AUTOSAR XML (schema 4-0-3)
standard types defined: Boolean, UInt16
package /AUTOSAR_Platform/DataConstrs
  range DC_Boolean: raw 0..1
  range DC_UInt16: raw 0..65535
package /PATAC/MSM/ComponentTypes
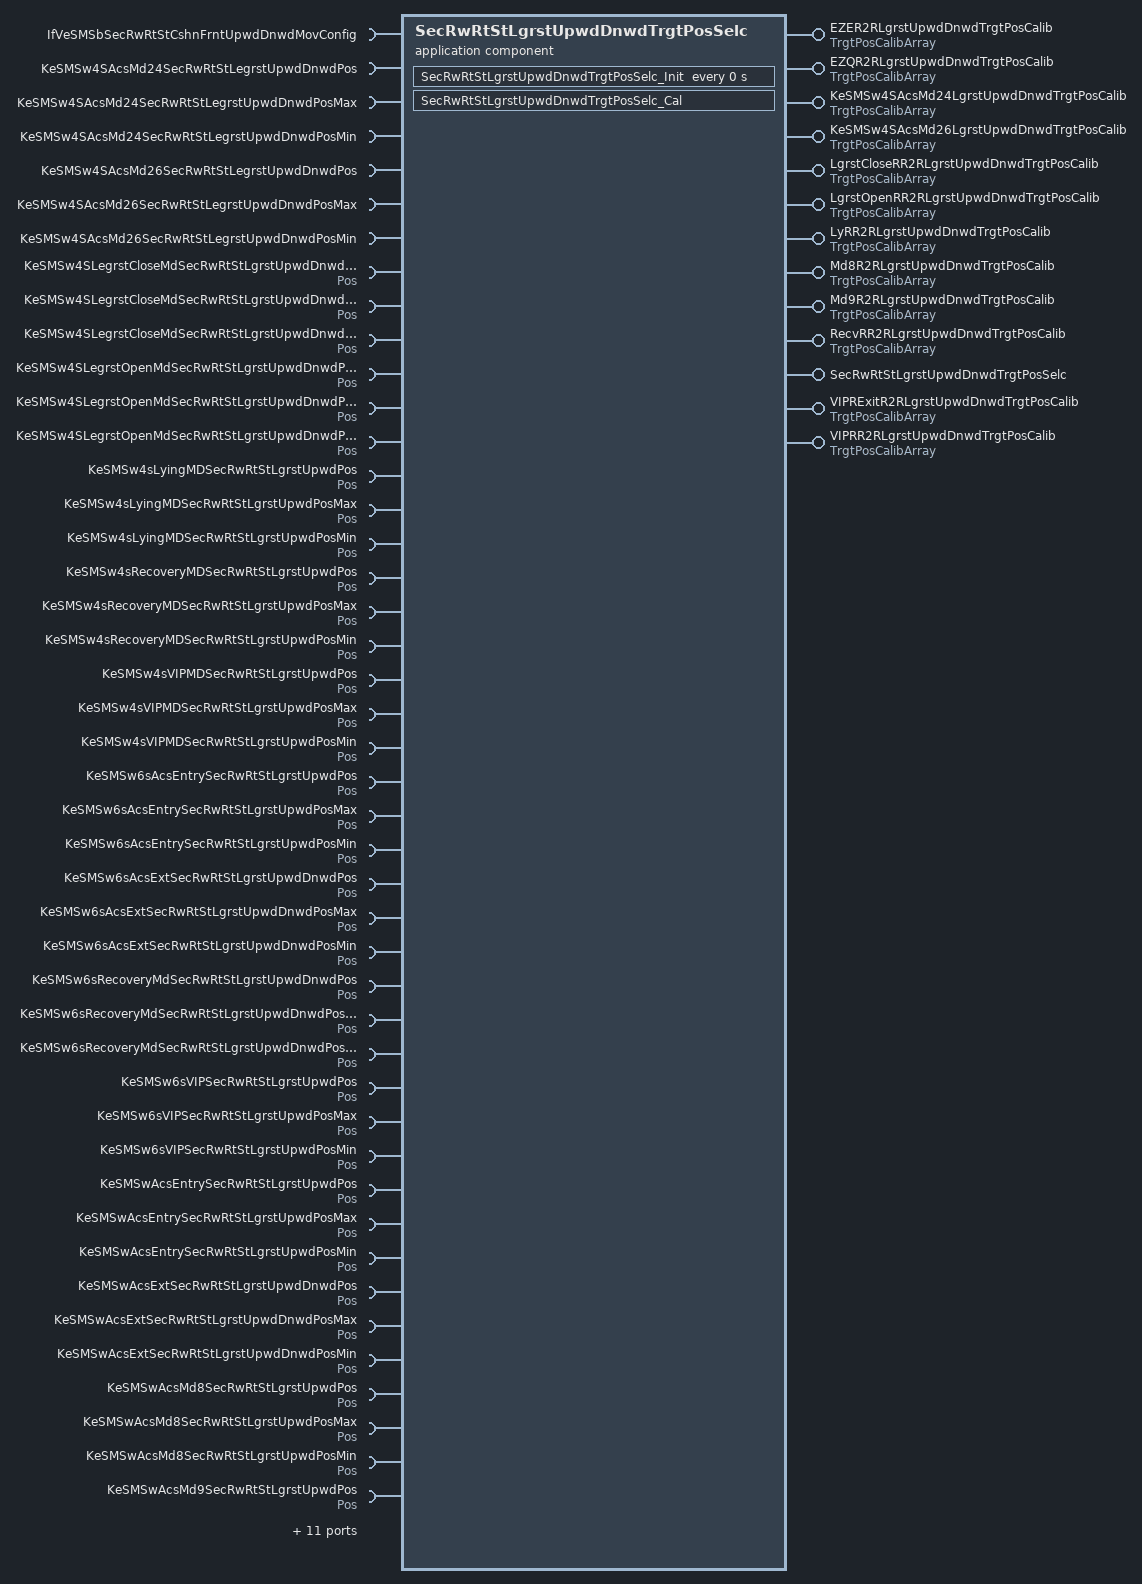
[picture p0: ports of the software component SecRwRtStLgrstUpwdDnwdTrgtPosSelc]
  application sw component type SecRwRtStLgrstUpwdDnwdTrgtPosSelc
    13 x provide port:
      EZER2RLgrstUpwdDnwdTrgtPosCalib: nonqueued-sender-com-spec{data-element=TrgtPosArray, init-value=[4095, 4095, 4095]}, provided-interface=TrgtPosCalibArray
      EZQR2RLgrstUpwdDnwdTrgtPosCalib: nonqueued-sender-com-spec{data-element=TrgtPosArray, init-value=[4095, 4095, 4095]}, provided-interface=TrgtPosCalibArray
      KeSMSw4SAcsMd24LgrstUpwdDnwdTrgtPosCalib: nonqueued-sender-com-spec{data-element=TrgtPosArray, init-value=[4095, 4095, 4095]}, provided-interface=TrgtPosCalibArray
      KeSMSw4SAcsMd26LgrstUpwdDnwdTrgtPosCalib: nonqueued-sender-com-spec{data-element=TrgtPosArray, init-value=[4095, 4095, 4095]}, provided-interface=TrgtPosCalibArray
      LgrstCloseRR2RLgrstUpwdDnwdTrgtPosCalib: nonqueued-sender-com-spec{data-element=TrgtPosArray, init-value=[4095, 4095, 4095]}, provided-interface=TrgtPosCalibArray
      LgrstOpenRR2RLgrstUpwdDnwdTrgtPosCalib: nonqueued-sender-com-spec{data-element=TrgtPosArray, init-value=[4095, 4095, 4095]}, provided-interface=TrgtPosCalibArray
      LyRR2RLgrstUpwdDnwdTrgtPosCalib: nonqueued-sender-com-spec{data-element=TrgtPosArray, init-value=[4095, 4095, 4095]}, provided-interface=TrgtPosCalibArray
      Md8R2RLgrstUpwdDnwdTrgtPosCalib: nonqueued-sender-com-spec{data-element=TrgtPosArray, init-value=[4095, 4095, 4095]}, provided-interface=TrgtPosCalibArray
      Md9R2RLgrstUpwdDnwdTrgtPosCalib: nonqueued-sender-com-spec{data-element=TrgtPosArray, init-value=[4095, 4095, 4095]}, provided-interface=TrgtPosCalibArray
      RecvRR2RLgrstUpwdDnwdTrgtPosCalib: nonqueued-sender-com-spec{data-element=TrgtPosArray, init-value=[4095, 4095, 4095]}, provided-interface=TrgtPosCalibArray
      SecRwRtStLgrstUpwdDnwdTrgtPosSelc: server-com-spec{operation=Cal, queue-length=1}, provided-interface=SecRwRtStLgrstUpwdDnwdTrgtPosSelc
      VIPRExitR2RLgrstUpwdDnwdTrgtPosCalib: nonqueued-sender-com-spec{data-element=TrgtPosArray, init-value=[4095, 4095, 4095]}, provided-interface=TrgtPosCalibArray
      VIPRR2RLgrstUpwdDnwdTrgtPosCalib: nonqueued-sender-com-spec{data-element=TrgtPosArray, init-value=[4095, 4095, 4095]}, provided-interface=TrgtPosCalibArray
    55 x require port:
      IfVeSMSbSecRwRtStCshnFrntUpwdDnwdMovConfig: nonqueued-receiver-com-spec{data-element=Val, filter=data-filter-type=ALWAYS, init-value=0}, required-interface=IfVeSMSbSecRwRtStCshnFrntUpwdDnwdMovConfig
      KeSMSw4SAcsMd24SecRwRtStLegrstUpwdDnwdPos: parameter-require-com-spec{init-value=0, parameter=KeSMSw4SAcsMd24SecRwRtStLegrstUpwdDnwdPos/Val}, required-interface=KeSMSw4SAcsMd24SecRwRtStLegrstUpwdDnwdPos
      KeSMSw4SAcsMd24SecRwRtStLegrstUpwdDnwdPosMax: parameter-require-com-spec{init-value=0, parameter=KeSMSw4SAcsMd24SecRwRtStLegrstUpwdDnwdPosMax/Val}, required-interface=KeSMSw4SAcsMd24SecRwRtStLegrstUpwdDnwdPosMax
      KeSMSw4SAcsMd24SecRwRtStLegrstUpwdDnwdPosMin: parameter-require-com-spec{init-value=0, parameter=KeSMSw4SAcsMd24SecRwRtStLegrstUpwdDnwdPosMin/Val}, required-interface=KeSMSw4SAcsMd24SecRwRtStLegrstUpwdDnwdPosMin
      KeSMSw4SAcsMd26SecRwRtStLegrstUpwdDnwdPos: parameter-require-com-spec{init-value=0, parameter=KeSMSw4SAcsMd26SecRwRtStLegrstUpwdDnwdPos/Val}, required-interface=KeSMSw4SAcsMd26SecRwRtStLegrstUpwdDnwdPos
      KeSMSw4SAcsMd26SecRwRtStLegrstUpwdDnwdPosMax: parameter-require-com-spec{init-value=0, parameter=KeSMSw4SAcsMd26SecRwRtStLegrstUpwdDnwdPosMax/Val}, required-interface=KeSMSw4SAcsMd26SecRwRtStLegrstUpwdDnwdPosMax
      KeSMSw4SAcsMd26SecRwRtStLegrstUpwdDnwdPosMin: parameter-require-com-spec{init-value=0, parameter=KeSMSw4SAcsMd26SecRwRtStLegrstUpwdDnwdPosMin/Val}, required-interface=KeSMSw4SAcsMd26SecRwRtStLegrstUpwdDnwdPosMin
      KeSMSw4SLegrstCloseMdSecRwRtStLgrstUpwdDnwdPos: parameter-require-com-spec{init-value=0, parameter=Pos/Val}, required-interface=Pos
      KeSMSw4SLegrstCloseMdSecRwRtStLgrstUpwdDnwdPosMax: parameter-require-com-spec{init-value=0, parameter=Pos/Val}, required-interface=Pos
      KeSMSw4SLegrstCloseMdSecRwRtStLgrstUpwdDnwdPosMin: parameter-require-com-spec{init-value=0, parameter=Pos/Val}, required-interface=Pos
      KeSMSw4SLegrstOpenMdSecRwRtStLgrstUpwdDnwdPos: parameter-require-com-spec{init-value=0, parameter=Pos/Val}, required-interface=Pos
      KeSMSw4SLegrstOpenMdSecRwRtStLgrstUpwdDnwdPosMax: parameter-require-com-spec{init-value=0, parameter=Pos/Val}, required-interface=Pos
      KeSMSw4SLegrstOpenMdSecRwRtStLgrstUpwdDnwdPosMin: parameter-require-com-spec{init-value=0, parameter=Pos/Val}, required-interface=Pos
      KeSMSw4sLyingMDSecRwRtStLgrstUpwdPos: parameter-require-com-spec{init-value=0, parameter=Pos/Val}, required-interface=Pos
      KeSMSw4sLyingMDSecRwRtStLgrstUpwdPosMax: parameter-require-com-spec{init-value=0, parameter=Pos/Val}, required-interface=Pos
      KeSMSw4sLyingMDSecRwRtStLgrstUpwdPosMin: parameter-require-com-spec{init-value=0, parameter=Pos/Val}, required-interface=Pos
      KeSMSw4sRecoveryMDSecRwRtStLgrstUpwdPos: parameter-require-com-spec{init-value=0, parameter=Pos/Val}, required-interface=Pos
      KeSMSw4sRecoveryMDSecRwRtStLgrstUpwdPosMax: parameter-require-com-spec{init-value=0, parameter=Pos/Val}, required-interface=Pos
      KeSMSw4sRecoveryMDSecRwRtStLgrstUpwdPosMin: parameter-require-com-spec{init-value=0, parameter=Pos/Val}, required-interface=Pos
      KeSMSw4sVIPMDSecRwRtStLgrstUpwdPos: parameter-require-com-spec{init-value=0, parameter=Pos/Val}, required-interface=Pos
      KeSMSw4sVIPMDSecRwRtStLgrstUpwdPosMax: parameter-require-com-spec{init-value=0, parameter=Pos/Val}, required-interface=Pos
      KeSMSw4sVIPMDSecRwRtStLgrstUpwdPosMin: parameter-require-com-spec{init-value=0, parameter=Pos/Val}, required-interface=Pos
      KeSMSw6sAcsEntrySecRwRtStLgrstUpwdPos: parameter-require-com-spec{init-value=0, parameter=Pos/Val}, required-interface=Pos
      KeSMSw6sAcsEntrySecRwRtStLgrstUpwdPosMax: parameter-require-com-spec{init-value=0, parameter=Pos/Val}, required-interface=Pos
      KeSMSw6sAcsEntrySecRwRtStLgrstUpwdPosMin: parameter-require-com-spec{init-value=0, parameter=Pos/Val}, required-interface=Pos
      KeSMSw6sAcsExtSecRwRtStLgrstUpwdDnwdPos: parameter-require-com-spec{init-value=0, parameter=Pos/Val}, required-interface=Pos
      KeSMSw6sAcsExtSecRwRtStLgrstUpwdDnwdPosMax: parameter-require-com-spec{init-value=0, parameter=Pos/Val}, required-interface=Pos
      KeSMSw6sAcsExtSecRwRtStLgrstUpwdDnwdPosMin: parameter-require-com-spec{init-value=0, parameter=Pos/Val}, required-interface=Pos
      KeSMSw6sRecoveryMdSecRwRtStLgrstUpwdDnwdPos: parameter-require-com-spec{init-value=0, parameter=Pos/Val}, required-interface=Pos
      KeSMSw6sRecoveryMdSecRwRtStLgrstUpwdDnwdPosMax: parameter-require-com-spec{init-value=0, parameter=Pos/Val}, required-interface=Pos
      KeSMSw6sRecoveryMdSecRwRtStLgrstUpwdDnwdPosMin: parameter-require-com-spec{init-value=0, parameter=Pos/Val}, required-interface=Pos
      KeSMSw6sVIPSecRwRtStLgrstUpwdPos: parameter-require-com-spec{init-value=4000, parameter=Pos/Val}, required-interface=Pos
      KeSMSw6sVIPSecRwRtStLgrstUpwdPosMax: parameter-require-com-spec{init-value=4000, parameter=Pos/Val}, required-interface=Pos
      KeSMSw6sVIPSecRwRtStLgrstUpwdPosMin: parameter-require-com-spec{init-value=20, parameter=Pos/Val}, required-interface=Pos
      KeSMSwAcsEntrySecRwRtStLgrstUpwdPos: parameter-require-com-spec{init-value=0, parameter=Pos/Val}, required-interface=Pos
      KeSMSwAcsEntrySecRwRtStLgrstUpwdPosMax: parameter-require-com-spec{init-value=0, parameter=Pos/Val}, required-interface=Pos
      KeSMSwAcsEntrySecRwRtStLgrstUpwdPosMin: parameter-require-com-spec{init-value=0, parameter=Pos/Val}, required-interface=Pos
      KeSMSwAcsExtSecRwRtStLgrstUpwdDnwdPos: parameter-require-com-spec{init-value=0, parameter=Pos/Val}, required-interface=Pos
      KeSMSwAcsExtSecRwRtStLgrstUpwdDnwdPosMax: parameter-require-com-spec{init-value=0, parameter=Pos/Val}, required-interface=Pos
      KeSMSwAcsExtSecRwRtStLgrstUpwdDnwdPosMin: parameter-require-com-spec{init-value=0, parameter=Pos/Val}, required-interface=Pos
      KeSMSwAcsMd8SecRwRtStLgrstUpwdPos: parameter-require-com-spec{init-value=0, parameter=Pos/Val}, required-interface=Pos
      KeSMSwAcsMd8SecRwRtStLgrstUpwdPosMax: parameter-require-com-spec{init-value=0, parameter=Pos/Val}, required-interface=Pos
      KeSMSwAcsMd8SecRwRtStLgrstUpwdPosMin: parameter-require-com-spec{init-value=0, parameter=Pos/Val}, required-interface=Pos
      KeSMSwAcsMd9SecRwRtStLgrstUpwdPos: parameter-require-com-spec{init-value=0, parameter=Pos/Val}, required-interface=Pos
      KeSMSwAcsMd9SecRwRtStLgrstUpwdPosMax: parameter-require-com-spec{init-value=0, parameter=Pos/Val}, required-interface=Pos
      KeSMSwAcsMd9SecRwRtStLgrstUpwdPosMin: parameter-require-com-spec{init-value=0, parameter=Pos/Val}, required-interface=Pos
      KeSMSwRecoveryMdSecRwRtStLgrstUpwdDnwdPos: parameter-require-com-spec{init-value=0, parameter=Pos/Val}, required-interface=Pos
      KeSMSwRecoveryMdSecRwRtStLgrstUpwdDnwdPosMax: parameter-require-com-spec{init-value=0, parameter=Pos/Val}, required-interface=Pos
      KeSMSwRecoveryMdSecRwRtStLgrstUpwdDnwdPosMin: parameter-require-com-spec{init-value=0, parameter=Pos/Val}, required-interface=Pos
      KeSMSwVIPSecRwRtStLgrstUpwdPos: parameter-require-com-spec{init-value=4000, parameter=Pos/Val}, required-interface=Pos
      KeSMSwVIPSecRwRtStLgrstUpwdPosMax: parameter-require-com-spec{init-value=4000, parameter=Pos/Val}, required-interface=Pos
      KeSMSwVIPSecRwRtStLgrstUpwdPosMin: parameter-require-com-spec{init-value=20, parameter=Pos/Val}, required-interface=Pos
      StNumFlg: required-interface=StNumFlg
        required-com-specs:
          data-element=Is4s, filter=data-filter-type=ALWAYS, init-value=0
          data-element=Is6s, filter=data-filter-type=ALWAYS, init-value=0
          data-element=Is6s7s, filter=data-filter-type=ALWAYS, init-value=0
          data-element=Is7s, filter=data-filter-type=ALWAYS, init-value=0
      VIPR557TrgtPos: required-com-specs=[VIPR557TrgtPos/Get, VIPR557TrgtPos/Set], required-interface=VIPR557TrgtPos
      VIPRExit557TrgtPos: required-com-specs=[VIPRExit557TrgtPos/Get, VIPRExit557TrgtPos/Set], required-interface=VIPRExit557TrgtPos
    behavior SecRwRtStLgrstUpwdDnwdTrgtPosSelc_InternalBehavior
      operation invoked event OIT_SecRwRtStLgrstUpwdDnwdTrgtPosSelc_Cal_SecRwRtStLgrstUpwdDnwdTrgtPosSelc_Cal: start-on-event=SecRwRtStLgrstUpwdDnwdTrgtPosSelc_Cal, operation=SecRwRtStLgrstUpwdDnwdTrgtPosSelc.Cal
      timing event SecRwRtStLgrstUpwdDnwdTrgtPosSelc_InitEvent: start-on-event=SecRwRtStLgrstUpwdDnwdTrgtPosSelc_Init, period=0
      runnable SecRwRtStLgrstUpwdDnwdTrgtPosSelc_Cal
        data-receive-point-by-arguments:
          5 x access:
            REC_IfVeSMSbSecRwRtStCshnFrntUpwdDnwdMovConfig_Val: accessed-variable=IfVeSMSbSecRwRtStCshnFrntUpwdDnwdMovConfig.Val
            REC_StNumFlg_Is4s: accessed-variable=StNumFlg.Is4s
            REC_StNumFlg_Is6s: accessed-variable=StNumFlg.Is6s
            REC_StNumFlg_Is6s7s: accessed-variable=StNumFlg.Is6s7s
            REC_StNumFlg_Is7s: accessed-variable=StNumFlg.Is7s
        data-send-points:
          12 x access:
            SEND_EZER2RLgrstUpwdDnwdTrgtPosCalib_TrgtPosArray: accessed-variable=EZER2RLgrstUpwdDnwdTrgtPosCalib.TrgtPosArray
            SEND_EZQR2RLgrstUpwdDnwdTrgtPosCalib_TrgtPosArray: accessed-variable=EZQR2RLgrstUpwdDnwdTrgtPosCalib.TrgtPosArray
            SEND_KeSMSw4SAcsMd24LgrstUpwdDnwdTrgtPosCalib_TrgtPosArray: accessed-variable=KeSMSw4SAcsMd24LgrstUpwdDnwdTrgtPosCalib.TrgtPosArray
            SEND_KeSMSw4SAcsMd26LgrstUpwdDnwdTrgtPosCalib_TrgtPosArray: accessed-variable=KeSMSw4SAcsMd26LgrstUpwdDnwdTrgtPosCalib.TrgtPosArray
            SEND_LgrstCloseRR2RLgrstUpwdDnwdTrgtPosCalib_TrgtPosArray: accessed-variable=LgrstCloseRR2RLgrstUpwdDnwdTrgtPosCalib.TrgtPosArray
            SEND_LgrstOpenRR2RLgrstUpwdDnwdTrgtPosCalib_TrgtPosArray: accessed-variable=LgrstOpenRR2RLgrstUpwdDnwdTrgtPosCalib.TrgtPosArray
            SEND_LyRR2RLgrstUpwdDnwdTrgtPosCalib_TrgtPosArray: accessed-variable=LyRR2RLgrstUpwdDnwdTrgtPosCalib.TrgtPosArray
            SEND_Md8R2RLgrstUpwdDnwdTrgtPosCalib_TrgtPosArray: accessed-variable=Md8R2RLgrstUpwdDnwdTrgtPosCalib.TrgtPosArray
            SEND_Md9R2RLgrstUpwdDnwdTrgtPosCalib_TrgtPosArray: accessed-variable=Md9R2RLgrstUpwdDnwdTrgtPosCalib.TrgtPosArray
            SEND_RecvRR2RLgrstUpwdDnwdTrgtPosCalib_TrgtPosArray: accessed-variable=RecvRR2RLgrstUpwdDnwdTrgtPosCalib.TrgtPosArray
            SEND_VIPRExitR2RLgrstUpwdDnwdTrgtPosCalib_TrgtPosArray: accessed-variable=VIPRExitR2RLgrstUpwdDnwdTrgtPosCalib.TrgtPosArray
            SEND_VIPRR2RLgrstUpwdDnwdTrgtPosCalib_TrgtPosArray: accessed-variable=VIPRR2RLgrstUpwdDnwdTrgtPosCalib.TrgtPosArray
        51 x parameter access:
          PA_KeSMSw4SAcsMd24SecRwRtStLegrstUpwdDnwdPos_Val: accessed-parameter=KeSMSw4SAcsMd24SecRwRtStLegrstUpwdDnwdPos.Val
          PA_KeSMSw4SAcsMd24SecRwRtStLegrstUpwdDnwdPosMax_Val: accessed-parameter=KeSMSw4SAcsMd24SecRwRtStLegrstUpwdDnwdPosMax.Val
          PA_KeSMSw4SAcsMd24SecRwRtStLegrstUpwdDnwdPosMin_Val: accessed-parameter=KeSMSw4SAcsMd24SecRwRtStLegrstUpwdDnwdPosMin.Val
          PA_KeSMSw4SAcsMd26SecRwRtStLegrstUpwdDnwdPos_Val: accessed-parameter=KeSMSw4SAcsMd26SecRwRtStLegrstUpwdDnwdPos.Val
          PA_KeSMSw4SAcsMd26SecRwRtStLegrstUpwdDnwdPosMax_Val: accessed-parameter=KeSMSw4SAcsMd26SecRwRtStLegrstUpwdDnwdPosMax.Val
          PA_KeSMSw4SAcsMd26SecRwRtStLegrstUpwdDnwdPosMin_Val: accessed-parameter=KeSMSw4SAcsMd26SecRwRtStLegrstUpwdDnwdPosMin.Val
          PA_KeSMSw4SLegrstCloseMdSecRwRtStLgrstUpwdDnwdPos_Val: accessed-parameter=KeSMSw4SLegrstCloseMdSecRwRtStLgrstUpwdDnwdPos.Val
          PA_KeSMSw4SLegrstCloseMdSecRwRtStLgrstUpwdDnwdPosMax_Val: accessed-parameter=KeSMSw4SLegrstCloseMdSecRwRtStLgrstUpwdDnwdPosMax.Val
          PA_KeSMSw4SLegrstCloseMdSecRwRtStLgrstUpwdDnwdPosMin_Val: accessed-parameter=KeSMSw4SLegrstCloseMdSecRwRtStLgrstUpwdDnwdPosMin.Val
          PA_KeSMSw4SLegrstOpenMdSecRwRtStLgrstUpwdDnwdPos_Val: accessed-parameter=KeSMSw4SLegrstOpenMdSecRwRtStLgrstUpwdDnwdPos.Val
          PA_KeSMSw4SLegrstOpenMdSecRwRtStLgrstUpwdDnwdPosMax_Val: accessed-parameter=KeSMSw4SLegrstOpenMdSecRwRtStLgrstUpwdDnwdPosMax.Val
          PA_KeSMSw4SLegrstOpenMdSecRwRtStLgrstUpwdDnwdPosMin_Val: accessed-parameter=KeSMSw4SLegrstOpenMdSecRwRtStLgrstUpwdDnwdPosMin.Val
          PA_KeSMSw4sLyingMDSecRwRtStLgrstUpwdPos_Val: accessed-parameter=KeSMSw4sLyingMDSecRwRtStLgrstUpwdPos.Val
          PA_KeSMSw4sLyingMDSecRwRtStLgrstUpwdPosMax_Val: accessed-parameter=KeSMSw4sLyingMDSecRwRtStLgrstUpwdPosMax.Val
          PA_KeSMSw4sLyingMDSecRwRtStLgrstUpwdPosMin_Val: accessed-parameter=KeSMSw4sLyingMDSecRwRtStLgrstUpwdPosMin.Val
          PA_KeSMSw4sRecoveryMDSecRwRtStLgrstUpwdPos_Val: accessed-parameter=KeSMSw4sRecoveryMDSecRwRtStLgrstUpwdPos.Val
          PA_KeSMSw4sRecoveryMDSecRwRtStLgrstUpwdPosMax_Val: accessed-parameter=KeSMSw4sRecoveryMDSecRwRtStLgrstUpwdPosMax.Val
          PA_KeSMSw4sRecoveryMDSecRwRtStLgrstUpwdPosMin_Val: accessed-parameter=KeSMSw4sRecoveryMDSecRwRtStLgrstUpwdPosMin.Val
          PA_KeSMSw4sVIPMDSecRwRtStLgrstUpwdPos_Val: accessed-parameter=KeSMSw4sVIPMDSecRwRtStLgrstUpwdPos.Val
          PA_KeSMSw4sVIPMDSecRwRtStLgrstUpwdPosMax_Val: accessed-parameter=KeSMSw4sVIPMDSecRwRtStLgrstUpwdPosMax.Val
          PA_KeSMSw4sVIPMDSecRwRtStLgrstUpwdPosMin_Val: accessed-parameter=KeSMSw4sVIPMDSecRwRtStLgrstUpwdPosMin.Val
          PA_KeSMSw6sAcsEntrySecRwRtStLgrstUpwdPos_Val: accessed-parameter=KeSMSw6sAcsEntrySecRwRtStLgrstUpwdPos.Val
          PA_KeSMSw6sAcsEntrySecRwRtStLgrstUpwdPosMax_Val: accessed-parameter=KeSMSw6sAcsEntrySecRwRtStLgrstUpwdPosMax.Val
          PA_KeSMSw6sAcsEntrySecRwRtStLgrstUpwdPosMin_Val: accessed-parameter=KeSMSw6sAcsEntrySecRwRtStLgrstUpwdPosMin.Val
          PA_KeSMSw6sAcsExtSecRwRtStLgrstUpwdDnwdPos_Val: accessed-parameter=KeSMSw6sAcsExtSecRwRtStLgrstUpwdDnwdPos.Val
          PA_KeSMSw6sAcsExtSecRwRtStLgrstUpwdDnwdPosMax_Val: accessed-parameter=KeSMSw6sAcsExtSecRwRtStLgrstUpwdDnwdPosMax.Val
          PA_KeSMSw6sAcsExtSecRwRtStLgrstUpwdDnwdPosMin_Val: accessed-parameter=KeSMSw6sAcsExtSecRwRtStLgrstUpwdDnwdPosMin.Val
          PA_KeSMSw6sRecoveryMdSecRwRtStLgrstUpwdDnwdPos_Val: accessed-parameter=KeSMSw6sRecoveryMdSecRwRtStLgrstUpwdDnwdPos.Val
          PA_KeSMSw6sRecoveryMdSecRwRtStLgrstUpwdDnwdPosMax_Val: accessed-parameter=KeSMSw6sRecoveryMdSecRwRtStLgrstUpwdDnwdPosMax.Val
          PA_KeSMSw6sRecoveryMdSecRwRtStLgrstUpwdDnwdPosMin_Val: accessed-parameter=KeSMSw6sRecoveryMdSecRwRtStLgrstUpwdDnwdPosMin.Val
          PA_KeSMSw6sVIPSecRwRtStLgrstUpwdPos_Val: accessed-parameter=KeSMSw6sVIPSecRwRtStLgrstUpwdPos.Val
          PA_KeSMSw6sVIPSecRwRtStLgrstUpwdPosMax_Val: accessed-parameter=KeSMSw6sVIPSecRwRtStLgrstUpwdPosMax.Val
          PA_KeSMSw6sVIPSecRwRtStLgrstUpwdPosMin_Val: accessed-parameter=KeSMSw6sVIPSecRwRtStLgrstUpwdPosMin.Val
          PA_KeSMSwAcsEntrySecRwRtStLgrstUpwdPos_Val: accessed-parameter=KeSMSwAcsEntrySecRwRtStLgrstUpwdPos.Val
          PA_KeSMSwAcsEntrySecRwRtStLgrstUpwdPosMax_Val: accessed-parameter=KeSMSwAcsEntrySecRwRtStLgrstUpwdPosMax.Val
          PA_KeSMSwAcsEntrySecRwRtStLgrstUpwdPosMin_Val: accessed-parameter=KeSMSwAcsEntrySecRwRtStLgrstUpwdPosMin.Val
          PA_KeSMSwAcsExtSecRwRtStLgrstUpwdDnwdPos_Val: accessed-parameter=KeSMSwAcsExtSecRwRtStLgrstUpwdDnwdPos.Val
          PA_KeSMSwAcsExtSecRwRtStLgrstUpwdDnwdPosMax_Val: accessed-parameter=KeSMSwAcsExtSecRwRtStLgrstUpwdDnwdPosMax.Val
          PA_KeSMSwAcsExtSecRwRtStLgrstUpwdDnwdPosMin_Val: accessed-parameter=KeSMSwAcsExtSecRwRtStLgrstUpwdDnwdPosMin.Val
          PA_KeSMSwAcsMd8SecRwRtStLgrstUpwdPos_Val: accessed-parameter=KeSMSwAcsMd8SecRwRtStLgrstUpwdPos.Val
          PA_KeSMSwAcsMd8SecRwRtStLgrstUpwdPosMax_Val: accessed-parameter=KeSMSwAcsMd8SecRwRtStLgrstUpwdPosMax.Val
          PA_KeSMSwAcsMd8SecRwRtStLgrstUpwdPosMin_Val: accessed-parameter=KeSMSwAcsMd8SecRwRtStLgrstUpwdPosMin.Val
          PA_KeSMSwAcsMd9SecRwRtStLgrstUpwdPos_Val: accessed-parameter=KeSMSwAcsMd9SecRwRtStLgrstUpwdPos.Val
          PA_KeSMSwAcsMd9SecRwRtStLgrstUpwdPosMax_Val: accessed-parameter=KeSMSwAcsMd9SecRwRtStLgrstUpwdPosMax.Val
          PA_KeSMSwAcsMd9SecRwRtStLgrstUpwdPosMin_Val: accessed-parameter=KeSMSwAcsMd9SecRwRtStLgrstUpwdPosMin.Val
          PA_KeSMSwRecoveryMdSecRwRtStLgrstUpwdDnwdPos_Val: accessed-parameter=KeSMSwRecoveryMdSecRwRtStLgrstUpwdDnwdPos.Val
          PA_KeSMSwRecoveryMdSecRwRtStLgrstUpwdDnwdPosMax_Val: accessed-parameter=KeSMSwRecoveryMdSecRwRtStLgrstUpwdDnwdPosMax.Val
          PA_KeSMSwRecoveryMdSecRwRtStLgrstUpwdDnwdPosMin_Val: accessed-parameter=KeSMSwRecoveryMdSecRwRtStLgrstUpwdDnwdPosMin.Val
          PA_KeSMSwVIPSecRwRtStLgrstUpwdPos_Val: accessed-parameter=KeSMSwVIPSecRwRtStLgrstUpwdPos.Val
          PA_KeSMSwVIPSecRwRtStLgrstUpwdPosMax_Val: accessed-parameter=KeSMSwVIPSecRwRtStLgrstUpwdPosMax.Val
          PA_KeSMSwVIPSecRwRtStLgrstUpwdPosMin_Val: accessed-parameter=KeSMSwVIPSecRwRtStLgrstUpwdPosMin.Val
        sync call SC_VIPR557TrgtPos_Get: operation=VIPR557TrgtPos.Get, timeout=0
        sync call SC_VIPRExit557TrgtPos_Get: operation=VIPRExit557TrgtPos.Get, timeout=0
      runnable SecRwRtStLgrstUpwdDnwdTrgtPosSelc_Init
        51 x parameter access:
          PA_KeSMSw4SAcsMd24SecRwRtStLegrstUpwdDnwdPos_Val: accessed-parameter=KeSMSw4SAcsMd24SecRwRtStLegrstUpwdDnwdPos.Val
          PA_KeSMSw4SAcsMd24SecRwRtStLegrstUpwdDnwdPosMax_Val: accessed-parameter=KeSMSw4SAcsMd24SecRwRtStLegrstUpwdDnwdPosMax.Val
          PA_KeSMSw4SAcsMd24SecRwRtStLegrstUpwdDnwdPosMin_Val: accessed-parameter=KeSMSw4SAcsMd24SecRwRtStLegrstUpwdDnwdPosMin.Val
          PA_KeSMSw4SAcsMd26SecRwRtStLegrstUpwdDnwdPos_Val: accessed-parameter=KeSMSw4SAcsMd26SecRwRtStLegrstUpwdDnwdPos.Val
          PA_KeSMSw4SAcsMd26SecRwRtStLegrstUpwdDnwdPosMax_Val: accessed-parameter=KeSMSw4SAcsMd26SecRwRtStLegrstUpwdDnwdPosMax.Val
          PA_KeSMSw4SAcsMd26SecRwRtStLegrstUpwdDnwdPosMin_Val: accessed-parameter=KeSMSw4SAcsMd26SecRwRtStLegrstUpwdDnwdPosMin.Val
          PA_KeSMSw4SLegrstCloseMdSecRwRtStLgrstUpwdDnwdPos_Val: accessed-parameter=KeSMSw4SLegrstCloseMdSecRwRtStLgrstUpwdDnwdPos.Val
          PA_KeSMSw4SLegrstCloseMdSecRwRtStLgrstUpwdDnwdPosMax_Val: accessed-parameter=KeSMSw4SLegrstCloseMdSecRwRtStLgrstUpwdDnwdPosMax.Val
          PA_KeSMSw4SLegrstCloseMdSecRwRtStLgrstUpwdDnwdPosMin_Val: accessed-parameter=KeSMSw4SLegrstCloseMdSecRwRtStLgrstUpwdDnwdPosMin.Val
          PA_KeSMSw4SLegrstOpenMdSecRwRtStLgrstUpwdDnwdPos_Val: accessed-parameter=KeSMSw4SLegrstOpenMdSecRwRtStLgrstUpwdDnwdPos.Val
          PA_KeSMSw4SLegrstOpenMdSecRwRtStLgrstUpwdDnwdPosMax_Val: accessed-parameter=KeSMSw4SLegrstOpenMdSecRwRtStLgrstUpwdDnwdPosMax.Val
          PA_KeSMSw4SLegrstOpenMdSecRwRtStLgrstUpwdDnwdPosMin_Val: accessed-parameter=KeSMSw4SLegrstOpenMdSecRwRtStLgrstUpwdDnwdPosMin.Val
          PA_KeSMSw4sLyingMDSecRwRtStLgrstUpwdPos_Val: accessed-parameter=KeSMSw4sLyingMDSecRwRtStLgrstUpwdPos.Val
          PA_KeSMSw4sLyingMDSecRwRtStLgrstUpwdPosMax_Val: accessed-parameter=KeSMSw4sLyingMDSecRwRtStLgrstUpwdPosMax.Val
          PA_KeSMSw4sLyingMDSecRwRtStLgrstUpwdPosMin_Val: accessed-parameter=KeSMSw4sLyingMDSecRwRtStLgrstUpwdPosMin.Val
          PA_KeSMSw4sRecoveryMDSecRwRtStLgrstUpwdPos_Val: accessed-parameter=KeSMSw4sRecoveryMDSecRwRtStLgrstUpwdPos.Val
          PA_KeSMSw4sRecoveryMDSecRwRtStLgrstUpwdPosMax_Val: accessed-parameter=KeSMSw4sRecoveryMDSecRwRtStLgrstUpwdPosMax.Val
          PA_KeSMSw4sRecoveryMDSecRwRtStLgrstUpwdPosMin_Val: accessed-parameter=KeSMSw4sRecoveryMDSecRwRtStLgrstUpwdPosMin.Val
          PA_KeSMSw4sVIPMDSecRwRtStLgrstUpwdPos_Val: accessed-parameter=KeSMSw4sVIPMDSecRwRtStLgrstUpwdPos.Val
          PA_KeSMSw4sVIPMDSecRwRtStLgrstUpwdPosMax_Val: accessed-parameter=KeSMSw4sVIPMDSecRwRtStLgrstUpwdPosMax.Val
          PA_KeSMSw4sVIPMDSecRwRtStLgrstUpwdPosMin_Val: accessed-parameter=KeSMSw4sVIPMDSecRwRtStLgrstUpwdPosMin.Val
          PA_KeSMSw6sAcsEntrySecRwRtStLgrstUpwdPos_Val: accessed-parameter=KeSMSw6sAcsEntrySecRwRtStLgrstUpwdPos.Val
          PA_KeSMSw6sAcsEntrySecRwRtStLgrstUpwdPosMax_Val: accessed-parameter=KeSMSw6sAcsEntrySecRwRtStLgrstUpwdPosMax.Val
          PA_KeSMSw6sAcsEntrySecRwRtStLgrstUpwdPosMin_Val: accessed-parameter=KeSMSw6sAcsEntrySecRwRtStLgrstUpwdPosMin.Val
          PA_KeSMSw6sAcsExtSecRwRtStLgrstUpwdDnwdPos_Val: accessed-parameter=KeSMSw6sAcsExtSecRwRtStLgrstUpwdDnwdPos.Val
          PA_KeSMSw6sAcsExtSecRwRtStLgrstUpwdDnwdPosMax_Val: accessed-parameter=KeSMSw6sAcsExtSecRwRtStLgrstUpwdDnwdPosMax.Val
          PA_KeSMSw6sAcsExtSecRwRtStLgrstUpwdDnwdPosMin_Val: accessed-parameter=KeSMSw6sAcsExtSecRwRtStLgrstUpwdDnwdPosMin.Val
          PA_KeSMSw6sRecoveryMdSecRwRtStLgrstUpwdDnwdPos_Val: accessed-parameter=KeSMSw6sRecoveryMdSecRwRtStLgrstUpwdDnwdPos.Val
          PA_KeSMSw6sRecoveryMdSecRwRtStLgrstUpwdDnwdPosMax_Val: accessed-parameter=KeSMSw6sRecoveryMdSecRwRtStLgrstUpwdDnwdPosMax.Val
          PA_KeSMSw6sRecoveryMdSecRwRtStLgrstUpwdDnwdPosMin_Val: accessed-parameter=KeSMSw6sRecoveryMdSecRwRtStLgrstUpwdDnwdPosMin.Val
          PA_KeSMSw6sVIPSecRwRtStLgrstUpwdPos_Val: accessed-parameter=KeSMSw6sVIPSecRwRtStLgrstUpwdPos.Val
          PA_KeSMSw6sVIPSecRwRtStLgrstUpwdPosMax_Val: accessed-parameter=KeSMSw6sVIPSecRwRtStLgrstUpwdPosMax.Val
          PA_KeSMSw6sVIPSecRwRtStLgrstUpwdPosMin_Val: accessed-parameter=KeSMSw6sVIPSecRwRtStLgrstUpwdPosMin.Val
          PA_KeSMSwAcsEntrySecRwRtStLgrstUpwdPos_Val: accessed-parameter=KeSMSwAcsEntrySecRwRtStLgrstUpwdPos.Val
          PA_KeSMSwAcsEntrySecRwRtStLgrstUpwdPosMax_Val: accessed-parameter=KeSMSwAcsEntrySecRwRtStLgrstUpwdPosMax.Val
          PA_KeSMSwAcsEntrySecRwRtStLgrstUpwdPosMin_Val: accessed-parameter=KeSMSwAcsEntrySecRwRtStLgrstUpwdPosMin.Val
          PA_KeSMSwAcsExtSecRwRtStLgrstUpwdDnwdPos_Val: accessed-parameter=KeSMSwAcsExtSecRwRtStLgrstUpwdDnwdPos.Val
          PA_KeSMSwAcsExtSecRwRtStLgrstUpwdDnwdPosMax_Val: accessed-parameter=KeSMSwAcsExtSecRwRtStLgrstUpwdDnwdPosMax.Val
          PA_KeSMSwAcsExtSecRwRtStLgrstUpwdDnwdPosMin_Val: accessed-parameter=KeSMSwAcsExtSecRwRtStLgrstUpwdDnwdPosMin.Val
          PA_KeSMSwAcsMd8SecRwRtStLgrstUpwdPos_Val: accessed-parameter=KeSMSwAcsMd8SecRwRtStLgrstUpwdPos.Val
          PA_KeSMSwAcsMd8SecRwRtStLgrstUpwdPosMax_Val: accessed-parameter=KeSMSwAcsMd8SecRwRtStLgrstUpwdPosMax.Val
          PA_KeSMSwAcsMd8SecRwRtStLgrstUpwdPosMin_Val: accessed-parameter=KeSMSwAcsMd8SecRwRtStLgrstUpwdPosMin.Val
          PA_KeSMSwAcsMd9SecRwRtStLgrstUpwdPos_Val: accessed-parameter=KeSMSwAcsMd9SecRwRtStLgrstUpwdPos.Val
          PA_KeSMSwAcsMd9SecRwRtStLgrstUpwdPosMax_Val: accessed-parameter=KeSMSwAcsMd9SecRwRtStLgrstUpwdPosMax.Val
          PA_KeSMSwAcsMd9SecRwRtStLgrstUpwdPosMin_Val: accessed-parameter=KeSMSwAcsMd9SecRwRtStLgrstUpwdPosMin.Val
          PA_KeSMSwRecoveryMdSecRwRtStLgrstUpwdDnwdPos_Val: accessed-parameter=KeSMSwRecoveryMdSecRwRtStLgrstUpwdDnwdPos.Val
          PA_KeSMSwRecoveryMdSecRwRtStLgrstUpwdDnwdPosMax_Val: accessed-parameter=KeSMSwRecoveryMdSecRwRtStLgrstUpwdDnwdPosMax.Val
          PA_KeSMSwRecoveryMdSecRwRtStLgrstUpwdDnwdPosMin_Val: accessed-parameter=KeSMSwRecoveryMdSecRwRtStLgrstUpwdDnwdPosMin.Val
          PA_KeSMSwVIPSecRwRtStLgrstUpwdPos_Val: accessed-parameter=KeSMSwVIPSecRwRtStLgrstUpwdPos.Val
          PA_KeSMSwVIPSecRwRtStLgrstUpwdPosMax_Val: accessed-parameter=KeSMSwVIPSecRwRtStLgrstUpwdPosMax.Val
          PA_KeSMSwVIPSecRwRtStLgrstUpwdPosMin_Val: accessed-parameter=KeSMSwVIPSecRwRtStLgrstUpwdPosMin.Val
  swc implementation SecRwRtStLgrstUpwdDnwdTrgtPosSelc_Implementation: behavior=SecRwRtStLgrstUpwdDnwdTrgtPosSelc_InternalBehavior
    code-descriptors:
      code Default: artifact-descriptors=autosar-engineering-object={short-label=Default, category=SWSRC}
package /PATAC/MSM/ModeAdjust/CalPortInterface
  7 x parameter interface:
    KeSMSw4SAcsMd24SecRwRtStLegrstUpwdDnwdPos
      parameter data prototype Val: sw-calibration-access=READ-WRITE, type=UInt16
    KeSMSw4SAcsMd24SecRwRtStLegrstUpwdDnwdPosMax
      parameter data prototype Val: sw-calibration-access=READ-WRITE, type=UInt16
    KeSMSw4SAcsMd24SecRwRtStLegrstUpwdDnwdPosMin
      parameter data prototype Val: sw-calibration-access=READ-WRITE, type=UInt16
    KeSMSw4SAcsMd26SecRwRtStLegrstUpwdDnwdPos
      parameter data prototype Val: sw-calibration-access=READ-WRITE, type=UInt16
    KeSMSw4SAcsMd26SecRwRtStLegrstUpwdDnwdPosMax
      parameter data prototype Val: sw-calibration-access=READ-WRITE, type=UInt16
    KeSMSw4SAcsMd26SecRwRtStLegrstUpwdDnwdPosMin
      parameter data prototype Val: sw-calibration-access=READ-WRITE, type=UInt16
    Pos
      parameter data prototype Val: sw-calibration-access=READ-WRITE, type=UInt16
package /PATAC/MSM/ModeAdjust/DataType
  impl type TrgtPosCalibArray: category=ARRAY, sw-calibration-access=READ-ONLY, type-emitter=RTE  # 0:pos 1:max 2:min
    element Element: array-size=3, array-size-semantics=FIXED-SIZE, implementation-data-type=UInt16, invalid-value=0
package /PATAC/MSM/ModeAdjust/PortInterface
  client server interface SecRwRtStLgrstUpwdDnwdTrgtPosSelc
    operation Cal
  client server interface VIPR557TrgtPos
    operation Get
      5 x arg, all with type=UInt16, direction=OUT, server-argument-impl-policy=USE-ARGUMENT-TYPE:
        SecRwLtStBkReclnTrgtPos
        SecRwLtStZeroTrgtPos
        SecRwLtStLgrstUpwdDnwdTrgtPos
        SecRwLtStLgrstInwdOtwdTrgtPos
        SecRwLtStFwdBkwdTrgtPos
    operation Set
      5 x arg, all with type=UInt16, direction=IN, server-argument-impl-policy=USE-ARGUMENT-TYPE:
        SecRwLtStBkReclnTrgtPos
        SecRwLtStZeroTrgtPos
        SecRwLtStLgrstUpwdDnwdTrgtPos
        SecRwLtStLgrstInwdOtwdTrgtPos
        SecRwLtStFwdBkwdTrgtPos
  client server interface VIPRExit557TrgtPos
    operation Get
      11 x arg, all with type=UInt16, direction=OUT, server-argument-impl-policy=USE-ARGUMENT-TYPE:
        SecRwRtStBkReclnTrgtPos
        SecRwRtStZeroTrgtPos
        SecRwRtStLgrstUpwdDnwdTrgtPos
        SecRwRtStLgrstInwdOtwdTrgtPos
        ThdRwLtStBkReclnTrgtPos
        ThdRwLtStFwdBkwdTrgtPos
        ThdRwRtStBkReclnTrgtPos
        ThdRwRtStFwdBkwdTrgtPos
        PassStBkReclnTrgtPos
        PassStFwdBkwdTrgtPos
        SecRwRtStFwdBkwdTrgtPos
    operation Set
  sender receiver interface StNumFlg
    4 x data, all with type=Boolean:
      Is4s
      Is6s
      Is6s7s
      Is7s
    invalidation-policys:
      data-element=Is4s, handle-invalid=DONT-INVALIDATE
      data-element=Is6s, handle-invalid=DONT-INVALIDATE
      data-element=Is6s7s, handle-invalid=DONT-INVALIDATE
      data-element=Is7s, handle-invalid=DONT-INVALIDATE
  sender receiver interface TrgtPosCalibArray: invalidation-policy{data-element=TrgtPosArray, handle-invalid=DONT-INVALIDATE}
    data TrgtPosArray: type=TrgtPosCalibArray  # 0:Pos 1:Max 2:Min
package /PATAC/MSM/PortInterfaces
  sender receiver interface IfVeSMSbSecRwRtStCshnFrntUpwdDnwdMovConfig: invalidation-policy{data-element=Val, handle-invalid=DONT-INVALIDATE}
    data Val: type=Boolean
